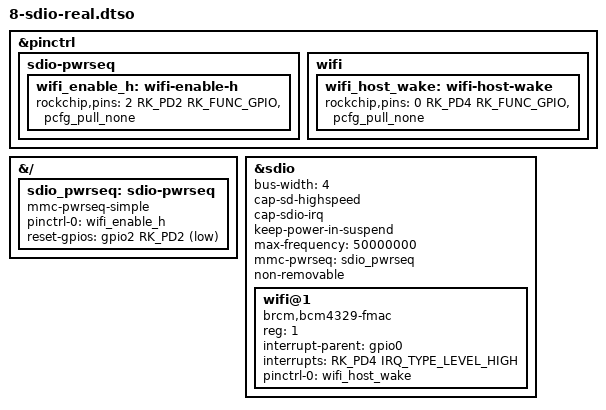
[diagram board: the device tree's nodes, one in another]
// SPDX-License-Identifier: (GPL-2.0+ OR MIT)
/dts-v1/; /plugin/;
#include <dt-bindings/gpio/gpio.h>
#include <dt-bindings/pinctrl/rockchip.h>
#include <dt-bindings/interrupt-controller/irq.h>
&pinctrl { sdio-pwrseq { wifi_enable_h: wifi-enable-h { rockchip,pins = <2 RK_PD2 RK_FUNC_GPIO &pcfg_pull_none>; }; };
  wifi { wifi_host_wake: wifi-host-wake { rockchip,pins = <0 RK_PD4 RK_FUNC_GPIO &pcfg_pull_none>; }; }; };
&{/} { sdio_pwrseq: sdio-pwrseq { compatible = "mmc-pwrseq-simple"; pinctrl-names = "default"; pinctrl-0 = <&wifi_enable_h>; reset-gpios = <&gpio2 RK_PD2 GPIO_ACTIVE_LOW>; }; };
&sdio { #address-cells = <1>; #size-cells = <0>; bus-width = <4>; cap-sd-highspeed; cap-sdio-irq; keep-power-in-suspend; max-frequency = <50000000>; mmc-pwrseq = <&sdio_pwrseq>; non-removable; status = "okay";
  wifi@1 { compatible = "brcm,bcm4329-fmac"; reg = <1>; interrupt-parent = <&gpio0>; interrupts = <RK_PD4 IRQ_TYPE_LEVEL_HIGH>; interrupt-names = "host-wake"; pinctrl-names = "default"; pinctrl-0 = <&wifi_host_wake>; }; };
